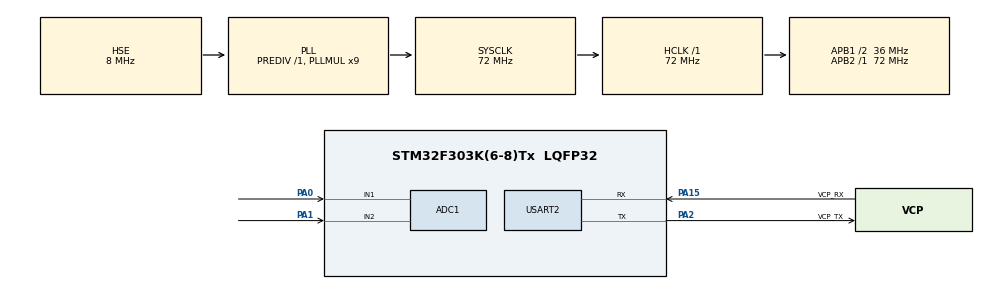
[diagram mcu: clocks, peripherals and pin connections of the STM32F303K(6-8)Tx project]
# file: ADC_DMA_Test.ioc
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ADC1.Channel-0\#ChannelRegularConversion=ADC_CHANNEL_1
ADC1.Channel-1\#ChannelRegularConversion=ADC_CHANNEL_2
ADC1.ClockPrescaler=ADC_CLOCK_SYNC_PCLK_DIV4
ADC1.ContinuousConvMode=ENABLE
ADC1.DMAContinuousRequests=ENABLE
ADC1.NbrOfConversion=2
ADC1.NbrOfConversionFlag=1
ADC1.Offset-0\#ChannelRegularConversion=0
ADC1.Offset-1\#ChannelRegularConversion=0
ADC1.OffsetNumber-0\#ChannelRegularConversion=ADC_OFFSET_NONE
ADC1.OffsetNumber-1\#ChannelRegularConversion=ADC_OFFSET_NONE
ADC1.Rank-0\#ChannelRegularConversion=1
ADC1.Rank-1\#ChannelRegularConversion=2
ADC1.SamplingTime-0\#ChannelRegularConversion=ADC_SAMPLETIME_61CYCLES_5
ADC1.SamplingTime-1\#ChannelRegularConversion=ADC_SAMPLETIME_61CYCLES_5
ADC1.SubFamily=STM32F303x8
ADC1.master=1
Dma.ADC1.0.Direction=DMA_PERIPH_TO_MEMORY
Dma.ADC1.0.Instance=DMA1_Channel1
Dma.ADC1.0.MemDataAlignment=DMA_MDATAALIGN_HALFWORD
Dma.ADC1.0.MemInc=DMA_MINC_ENABLE
Dma.ADC1.0.Mode=DMA_CIRCULAR
Dma.ADC1.0.PeriphDataAlignment=DMA_PDATAALIGN_HALFWORD
Dma.ADC1.0.PeriphInc=DMA_PINC_DISABLE
Dma.ADC1.0.Priority=DMA_PRIORITY_LOW
Dma.Request0=ADC1
Mcu.Family=STM32F3
Mcu.Name=STM32F303K(6-8)Tx
Mcu.Package=LQFP32
NVIC.DMA1_Channel1_IRQn=true\:0\:0\:false\:false\:true\:false\:true
NVIC.PriorityGroup=NVIC_PRIORITYGROUP_4
PA0.Mode=IN1-Single-Ended
PA0.Signal=ADC1_IN1
PA1.Mode=IN2-Single-Ended
PA1.Signal=ADC1_IN2
PA13.GPIO_Label=SWDIO
PA13.Mode=Serial_Wire
PA13.Signal=SYS_JTMS-SWDIO
PA14.GPIO_Label=SWCLK
PA14.Mode=Serial_Wire
PA14.Signal=SYS_JTCK-SWCLK
PA15.GPIO_Label=VCP_RX
PA15.Mode=Asynchronous
PA15.Signal=USART2_RX
PA2.GPIO_Label=VCP_TX
PA2.Mode=Asynchronous
PA2.Signal=USART2_TX
PF0\ /\ OSC_IN.Mode=HSE-External-Oscillator
PF0\ /\ OSC_IN.Signal=RCC_OSC_IN
PF1\ /\ OSC_OUT.Mode=HSE-External-Oscillator
PF1\ /\ OSC_OUT.Signal=RCC_OSC_OUT
ProjectManager.HeapSize=0x200
ProjectManager.StackSize=0x400
ProjectManager.TargetToolchain=TrueSTUDIO
RCC.AHBFreq_Value=72000000
RCC.APB1CLKDivider=RCC_HCLK_DIV2
RCC.APB1Freq_Value=36000000
RCC.APB1TimFreq_Value=72000000
RCC.APB2Freq_Value=72000000
RCC.APB2TimFreq_Value=72000000
RCC.CortexFreq_Value=72000000
RCC.HCLKFreq_Value=72000000
RCC.HSE_VALUE=8000000
RCC.HSI_VALUE=8000000
RCC.PLLMUL=RCC_PLL_MUL9
RCC.PLLSourceVirtual=RCC_PLLSOURCE_HSE
RCC.SYSCLKFreq_VALUE=72000000
RCC.SYSCLKSourceVirtual=RCC_SYSCLKSOURCE_PLLCLK
USART2.VirtualMode-Asynchronous=VM_ASYNC
board=NUCLEO-F303K8

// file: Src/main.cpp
/* USER CODE BEGIN Header */
/**
  ******************************************************************************
  * @file           : main.c
  * @brief          : Main program body
  ******************************************************************************
  * @attention
  *
  * <h2><center>&copy; Copyright (c) 2019 STMicroelectronics.
  * All rights reserved.</center></h2>
  *
  * This software component is licensed by ST under BSD 3-Clause license,
  * the "License"; You may not use this file except in compliance with the
  * License. You may obtain a copy of the License at:
  *                        opensource.org/licenses/BSD-3-Clause
  *
  ******************************************************************************
  */
/* USER CODE END Header */

#include "main.h"
#include "adc.h"
#include "dma.h"
#include "usart.h"
#include "gpio.h"

/* USER CODE BEGIN Includes */
#include "stdio.h"
/* USER CODE END Includes */

/* USER CODE BEGIN PTD */
uint16_t adcValue[2]={0,};
/* USER CODE END PTD */

/* USER CODE BEGIN PV */
void HAL_ADC_ConvCpltCallback(ADC_HandleTypeDef* hadc){
  // 処理
	//HAL_ADC_Start_DMA(&hadc1, (uint32_t *)adcValue, 2);
}
/* USER CODE END PV */

void SystemClock_Config(void);

int main(void)
{
  /* USER CODE BEGIN 1 */
	 setbuf(stdout, NULL);
  /* USER CODE END 1 */

  /* MCU Configuration--------------------------------------------------------*/

  /* Reset of all peripherals, Initializes the Flash interface and the Systick. */
  HAL_Init();

  /* Configure the system clock */
  SystemClock_Config();

  /* Initialize all configured peripherals */
  MX_GPIO_Init();
  MX_DMA_Init();
  MX_ADC1_Init();
  MX_USART2_UART_Init();
  /* USER CODE BEGIN 2 */
  HAL_ADC_Start_DMA(&hadc1,(uint32_t*)adcValue, 2);
  /* USER CODE END 2 */

  /* Infinite loop */
  while (1)
  {

    /* USER CODE BEGIN 3 */
	  printf("vaule1:%d value2:%d\n\r",adcValue[0],adcValue[1]);
  }
  /* USER CODE END 3 */
}

void SystemClock_Config(void)
{
  RCC_OscInitTypeDef RCC_OscInitStruct = {0};
  RCC_ClkInitTypeDef RCC_ClkInitStruct = {0};

  /** Initializes the CPU, AHB and APB busses clocks
  */
  RCC_OscInitStruct.OscillatorType = RCC_OSCILLATORTYPE_HSE;
  RCC_OscInitStruct.HSEState = RCC_HSE_ON;
  RCC_OscInitStruct.HSEPredivValue = RCC_HSE_PREDIV_DIV1;
  RCC_OscInitStruct.HSIState = RCC_HSI_ON;
  RCC_OscInitStruct.PLL.PLLState = RCC_PLL_ON;
  RCC_OscInitStruct.PLL.PLLSource = RCC_PLLSOURCE_HSE;
  RCC_OscInitStruct.PLL.PLLMUL = RCC_PLL_MUL9;
  if (HAL_RCC_OscConfig(&RCC_OscInitStruct) != HAL_OK)
  {
    Error_Handler();
  }
  /** Initializes the CPU, AHB and APB busses clocks
  */
  RCC_ClkInitStruct.ClockType = RCC_CLOCKTYPE_HCLK|RCC_CLOCKTYPE_SYSCLK
                              |RCC_CLOCKTYPE_PCLK1|RCC_CLOCKTYPE_PCLK2;
  RCC_ClkInitStruct.SYSCLKSource = RCC_SYSCLKSOURCE_PLLCLK;
  RCC_ClkInitStruct.AHBCLKDivider = RCC_SYSCLK_DIV1;
  RCC_ClkInitStruct.APB1CLKDivider = RCC_HCLK_DIV2;
  RCC_ClkInitStruct.APB2CLKDivider = RCC_HCLK_DIV1;

  if (HAL_RCC_ClockConfig(&RCC_ClkInitStruct, FLASH_LATENCY_2) != HAL_OK)
  {
    Error_Handler();
  }
}

void Error_Handler(void)
{
}

/************************ (C) COPYRIGHT STMicroelectronics *****END OF FILE****/
